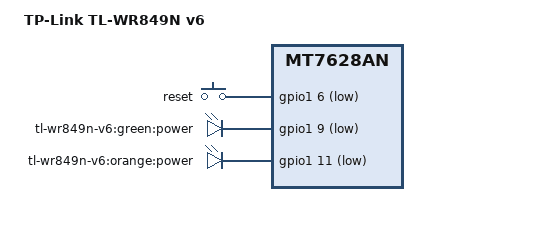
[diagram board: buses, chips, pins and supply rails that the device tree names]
/dts-v1/;

#include "TPLINK-4M-LF.dtsi"

#include <dt-bindings/gpio/gpio.h>
#include <dt-bindings/input/input.h>

/ {
	compatible = "tplink,tl-wr849n-v6", "mediatek,mt7628an-soc";
	model = "TP-Link TL-WR849N v6";

	aliases {
		led-boot = &led_power_green;
		led-failsafe = &led_power_green;
		led-running = &led_power_green;
		led-upgrade = &led_power_green;
	};

	keys {
		compatible = "gpio-keys-polled";
		poll-interval = <20>;

		reset {
			label = "reset";
			gpios = <&gpio1 6 GPIO_ACTIVE_LOW>;
			linux,code = <KEY_RESTART>;
		};
	};
	/* LED used is dual-color,dual lead LED */
	leds {
		compatible = "gpio-leds";

		led_power_green: power {
			label = "tl-wr849n-v6:green:power";
			gpios = <&gpio1 9 GPIO_ACTIVE_LOW>;
		};

		orange {
			label = "tl-wr849n-v6:orange:power";
			gpios = <&gpio1 11 GPIO_ACTIVE_LOW>;
		};
	};
};

&pinctrl {
	state_default: pinctrl0 {
		gpio {
			ralink,group = "p0led_an", "p2led_an", "perst";
			ralink,function = "gpio";
		};
	};
};
